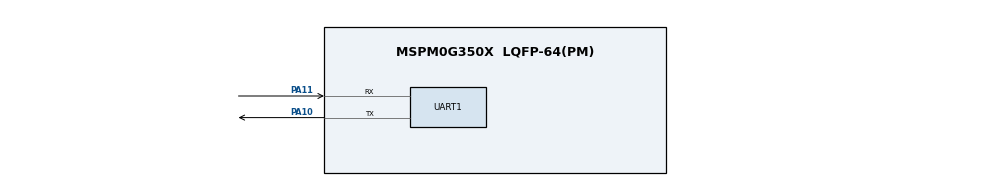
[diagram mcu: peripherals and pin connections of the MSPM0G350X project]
/**
 * @cliArgs --device "MSPM0G350X" --part "Default" --package "LQFP-64(PM)" --product "mspm0_sdk@2.02.00.05"
 * @versions {"tool":"1.21.1+3772"}
 */

/**
 * Import the modules used in this configuration.
 */
const GPIO    = scripting.addModule("/ti/driverlib/GPIO", {}, false);
const GPIO1   = GPIO.addInstance();
const GPIO2   = GPIO.addInstance();
const SYSCTL  = scripting.addModule("/ti/driverlib/SYSCTL");
const SYSTICK = scripting.addModule("/ti/driverlib/SYSTICK");
const UART    = scripting.addModule("/ti/driverlib/UART", {}, false);
const UART1   = UART.addInstance();

/**
 * Write custom configuration values to the imported modules.
 */
const gate7  = system.clockTree["MFCLKGATE"];
gate7.enable = true;

GPIO1.$name                              = "LED1";
GPIO1.port                               = "PORTA";
GPIO1.associatedPins[0].$name            = "PIN_14";
GPIO1.associatedPins[0].internalResistor = "PULL_DOWN";
GPIO1.associatedPins[0].assignedPin      = "14";

const Board = scripting.addModule("/ti/driverlib/Board", {}, false);

GPIO2.$name                          = "LCD";
GPIO2.port                           = "PORTA";
GPIO2.associatedPins.create(8);
GPIO2.associatedPins[0].$name        = "SCL";
GPIO2.associatedPins[0].initialValue = "SET";
GPIO2.associatedPins[0].assignedPin  = "12";
GPIO2.associatedPins[1].$name        = "SDA";
GPIO2.associatedPins[1].initialValue = "SET";
GPIO2.associatedPins[1].assignedPin  = "13";
GPIO2.associatedPins[2].$name        = "RES";
GPIO2.associatedPins[2].initialValue = "SET";
GPIO2.associatedPins[2].assignedPin  = "15";
GPIO2.associatedPins[3].$name        = "DC";
GPIO2.associatedPins[3].initialValue = "SET";
GPIO2.associatedPins[3].assignedPin  = "16";
GPIO2.associatedPins[4].$name        = "CS1";
GPIO2.associatedPins[4].initialValue = "SET";
GPIO2.associatedPins[4].assignedPin  = "21";
GPIO2.associatedPins[5].$name        = "BLK";
GPIO2.associatedPins[5].initialValue = "SET";
GPIO2.associatedPins[5].assignedPin  = "17";
GPIO2.associatedPins[6].$name        = "FSO";
GPIO2.associatedPins[6].direction    = "INPUT";
GPIO2.associatedPins[6].assignedPin  = "18";
GPIO2.associatedPins[7].$name        = "CS2";
GPIO2.associatedPins[7].initialValue = "SET";
GPIO2.associatedPins[7].assignedPin  = "22";

SYSCTL.forceDefaultClkConfig = true;
SYSCTL.clockTreeEn           = true;

SYSTICK.periodEnable      = true;
SYSTICK.systickEnable     = true;
SYSTICK.interruptPriority = "0";
SYSTICK.period            = 32;

UART1.$name                    = "UART_0";
UART1.uartClkSrc               = "MFCLK";
UART1.enabledInterrupts        = ["RX"];
UART1.peripheral.$assign       = "UART0";
UART1.peripheral.rxPin.$assign = "PA11";
UART1.peripheral.txPin.$assign = "PA10";
UART1.txPinConfig.$name        = "ti_driverlib_gpio_GPIOPinGeneric0";
UART1.rxPinConfig.$name        = "ti_driverlib_gpio_GPIOPinGeneric1";

/**
 * Pinmux solution for unlocked pins/peripherals. This ensures that minor changes to the automatic solver in a future
 * version of the tool will not impact the pinmux you originally saw.  These lines can be completely deleted in order to
 * re-solve from scratch.
 */
GPIO1.associatedPins[0].pin.$suggestSolution = "PA14";
Board.peripheral.$suggestSolution            = "DEBUGSS";
Board.peripheral.swclkPin.$suggestSolution   = "PA20";
Board.peripheral.swdioPin.$suggestSolution   = "PA19";
GPIO2.associatedPins[0].pin.$suggestSolution = "PA12";
GPIO2.associatedPins[1].pin.$suggestSolution = "PA13";
GPIO2.associatedPins[2].pin.$suggestSolution = "PA15";
GPIO2.associatedPins[3].pin.$suggestSolution = "PA16";
GPIO2.associatedPins[4].pin.$suggestSolution = "PA21";
GPIO2.associatedPins[5].pin.$suggestSolution = "PA17";
GPIO2.associatedPins[6].pin.$suggestSolution = "PA18";
GPIO2.associatedPins[7].pin.$suggestSolution = "PA22";
